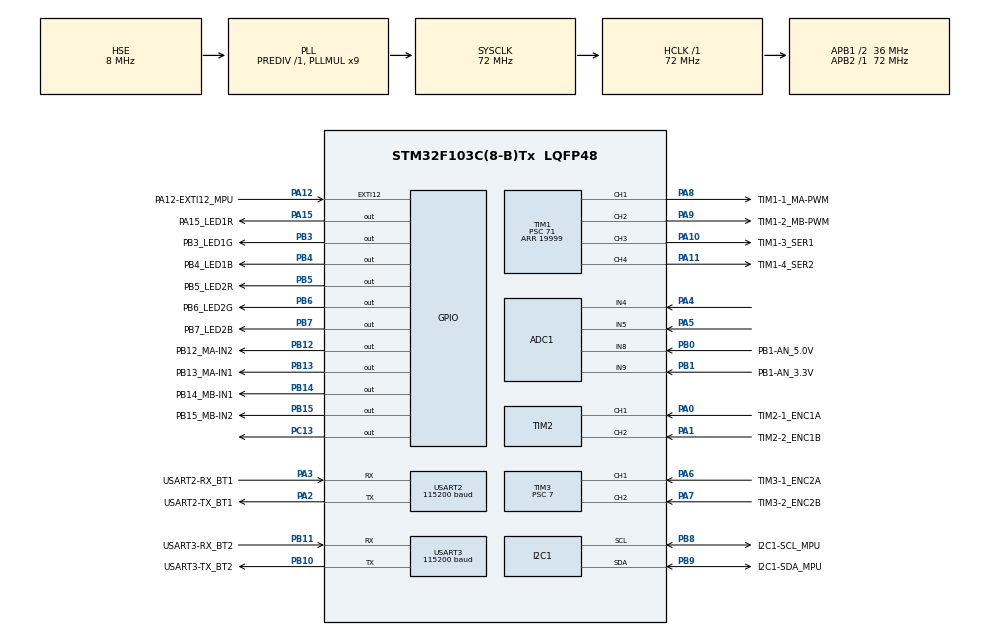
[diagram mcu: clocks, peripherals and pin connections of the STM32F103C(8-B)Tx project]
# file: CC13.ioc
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ADC1.Channel-3\#ChannelRegularConversion=ADC_CHANNEL_5
ADC1.Channel-4\#ChannelRegularConversion=ADC_CHANNEL_4
ADC1.Channel-5\#ChannelRegularConversion=ADC_CHANNEL_4
ADC1.NbrOfConversion=3
ADC1.NbrOfConversionFlag=1
ADC1.Rank-3\#ChannelRegularConversion=1
ADC1.Rank-4\#ChannelRegularConversion=2
ADC1.Rank-5\#ChannelRegularConversion=3
ADC1.SamplingTime-3\#ChannelRegularConversion=ADC_SAMPLETIME_1CYCLE_5
ADC1.SamplingTime-4\#ChannelRegularConversion=ADC_SAMPLETIME_1CYCLE_5
ADC1.SamplingTime-5\#ChannelRegularConversion=ADC_SAMPLETIME_1CYCLE_5
ADC1.master=1
Dma.ADC1.0.Direction=DMA_PERIPH_TO_MEMORY
Dma.ADC1.0.Instance=DMA1_Channel1
Dma.ADC1.0.MemDataAlignment=DMA_MDATAALIGN_WORD
Dma.ADC1.0.MemInc=DMA_MINC_ENABLE
Dma.ADC1.0.Mode=DMA_CIRCULAR
Dma.ADC1.0.PeriphDataAlignment=DMA_PDATAALIGN_WORD
Dma.ADC1.0.PeriphInc=DMA_PINC_DISABLE
Dma.ADC1.0.Priority=DMA_PRIORITY_LOW
Dma.Request0=ADC1
I2C1.I2C_Mode=I2C_Fast
Mcu.Family=STM32F1
Mcu.Name=STM32F103C(8-B)Tx
Mcu.Package=LQFP48
NVIC.DMA1_Channel1_IRQn=true\:0\:0\:false\:false\:true\:false\:true
NVIC.PriorityGroup=NVIC_PRIORITYGROUP_4
NVIC.USART2_IRQn=true\:0\:0\:false\:false\:true\:true\:true
NVIC.USART3_IRQn=true\:0\:0\:false\:false\:true\:true\:true
PA0-WKUP.GPIO_Label=TIM2-1_ENC1A
PA0-WKUP.Signal=S_TIM2_CH1_ETR
PA1.GPIO_Label=TIM2-2_ENC1B
PA1.Signal=S_TIM2_CH2
PA10.GPIO_Label=TIM1-3_SER1
PA10.Signal=S_TIM1_CH3
PA11.GPIO_Label=TIM1-4_SER2
PA11.Signal=S_TIM1_CH4
PA12.GPIO_Label=PA12-EXTI12_MPU
PA12.Signal=GPXTI12
PA13.Mode=Serial_Wire
PA13.Signal=SYS_JTMS-SWDIO
PA14.Mode=Serial_Wire
PA14.Signal=SYS_JTCK-SWCLK
PA15.GPIO_Label=PA15_LED1R
PA15.Signal=GPIO_Output
PA2.GPIO_Label=USART2-TX_BT1
PA2.Mode=Asynchronous
PA2.Signal=USART2_TX
PA3.GPIO_Label=USART2-RX_BT1
PA3.Mode=Asynchronous
PA3.Signal=USART2_RX
PA4.Signal=ADCx_IN4
PA5.Signal=ADCx_IN5
PA6.GPIO_Label=TIM3-1_ENC2A
PA6.Signal=S_TIM3_CH1
PA7.GPIO_Label=TIM3-2_ENC2B
PA7.Signal=S_TIM3_CH2
PA8.GPIO_Label=TIM1-1_MA-PWM
PA8.Signal=S_TIM1_CH1
PA9.GPIO_Label=TIM1-2_MB-PWM
PA9.Signal=S_TIM1_CH2
PB0.GPIO_Label=PB1-AN_5.0V
PB0.Signal=ADCx_IN8
PB1.GPIO_Label=PB1-AN_3.3V
PB1.Signal=ADCx_IN9
PB10.GPIO_Label=USART3-TX_BT2
PB10.Mode=Asynchronous
PB10.Signal=USART3_TX
PB11.GPIO_Label=USART3-RX_BT2
PB11.Mode=Asynchronous
PB11.Signal=USART3_RX
PB12.GPIO_Label=PB12_MA-IN2
PB12.Signal=GPIO_Output
PB13.GPIO_Label=PB13_MA-IN1
PB13.Signal=GPIO_Output
PB14.GPIO_Label=PB14_MB-IN1
PB14.Signal=GPIO_Output
PB15.GPIO_Label=PB15_MB-IN2
PB15.Signal=GPIO_Output
PB3.GPIO_Label=PB3_LED1G
PB3.Signal=GPIO_Output
PB4.GPIO_Label=PB4_LED1B
PB4.Signal=GPIO_Output
PB5.GPIO_Label=PB5_LED2R
PB5.Signal=GPIO_Output
PB6.GPIO_Label=PB6_LED2G
PB6.Signal=GPIO_Output
PB7.GPIO_Label=PB7_LED2B
PB7.Signal=GPIO_Output
PB8.GPIO_Label=I2C1-SCL_MPU
PB8.Mode=I2C
PB8.Signal=I2C1_SCL
PB9.GPIO_Label=I2C1-SDA_MPU
PB9.Mode=I2C
PB9.Signal=I2C1_SDA
PC13-TAMPER-RTC.Signal=GPIO_Output
PD0-OSC_IN.Mode=HSE-External-Oscillator
PD0-OSC_IN.Signal=RCC_OSC_IN
PD1-OSC_OUT.Mode=HSE-External-Oscillator
PD1-OSC_OUT.Signal=RCC_OSC_OUT
ProjectManager.HeapSize=0x200
ProjectManager.StackSize=0x400
ProjectManager.TargetToolchain=STM32CubeIDE
RCC.ADCPresc=RCC_ADCPCLK2_DIV6
RCC.AHBFreq_Value=72000000
RCC.APB1CLKDivider=RCC_HCLK_DIV2
RCC.APB1Freq_Value=36000000
RCC.APB1TimFreq_Value=72000000
RCC.APB2Freq_Value=72000000
RCC.APB2TimFreq_Value=72000000
RCC.EnbaleCSS=true
RCC.HCLKFreq_Value=72000000
RCC.PLLMUL=RCC_PLL_MUL9
RCC.PLLSourceVirtual=RCC_PLLSOURCE_HSE
RCC.SYSCLKFreq_VALUE=72000000
RCC.SYSCLKSource=RCC_SYSCLKSOURCE_PLLCLK
RCC.USBFreq_Value=48000000
RCC.USBPrescaler=RCC_USBCLKSOURCE_PLL_DIV1_5
SH.ADCx_IN4.0=ADC1_IN4,IN4
SH.ADCx_IN5.0=ADC1_IN5,IN5
SH.ADCx_IN8.0=ADC1_IN8,IN8
SH.ADCx_IN9.0=ADC1_IN9,IN9
SH.S_TIM1_CH1.0=TIM1_CH1,PWM Generation1 CH1
SH.S_TIM1_CH2.0=TIM1_CH2,PWM Generation2 CH2
SH.S_TIM1_CH3.0=TIM1_CH3,PWM Generation3 CH3
SH.S_TIM1_CH4.0=TIM1_CH4,PWM Generation4 CH4
SH.S_TIM2_CH1_ETR.0=TIM2_CH1,Encoder_Interface
SH.S_TIM2_CH2.0=TIM2_CH2,Encoder_Interface
SH.S_TIM3_CH1.0=TIM3_CH1,Encoder_Interface
SH.S_TIM3_CH2.0=TIM3_CH2,Encoder_Interface
TIM1.AutoReloadPreload=TIM_AUTORELOAD_PRELOAD_ENABLE
TIM1.Channel-PWM\ Generation1\ CH1=TIM_CHANNEL_1
TIM1.Channel-PWM\ Generation2\ CH2=TIM_CHANNEL_2
TIM1.Channel-PWM\ Generation3\ CH3=TIM_CHANNEL_3
TIM1.Channel-PWM\ Generation4\ CH4=TIM_CHANNEL_4
TIM1.Period=19999
TIM1.Prescaler=71
TIM1.Pulse-PWM\ Generation1\ CH1=0
TIM1.Pulse-PWM\ Generation2\ CH2=0
TIM1.Pulse-PWM\ Generation3\ CH3=0
TIM1.Pulse-PWM\ Generation4\ CH4=0
TIM2.IC1Filter=15
TIM2.IC2Filter=15
TIM3.Period=49999
TIM3.Prescaler=7
TIM4.AutoReloadPreload=TIM_AUTORELOAD_PRELOAD_ENABLE
TIM4.Period=36000
TIM4.Prescaler=0
USART2.BaudRate=115200
USART2.VirtualMode=VM_ASYNC
USART3.BaudRate=115200
USART3.VirtualMode=VM_ASYNC
VP_TIM1_VS_ClockSourceINT.Mode=Internal
VP_TIM4_VS_ClockSourceINT.Mode=Internal
board=custom

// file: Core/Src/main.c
/* USER CODE BEGIN Header */
/**
  ******************************************************************************
  * @file           : main.c
  * @brief          : Main program body
  ******************************************************************************
  * @attention
  *
  * <h2><center>&copy; Copyright (c) 2020 STMicroelectronics.
  * All rights reserved.</center></h2>
  *
  * This software component is licensed by ST under BSD 3-Clause license,
  * the "License"; You may not use this file except in compliance with the
  * License. You may obtain a copy of the License at:
  *                        opensource.org/licenses/BSD-3-Clause
  *
  ******************************************************************************
  */
/* USER CODE END Header */

#include "main.h"
#include "adc.h"
#include "dma.h"
#include "i2c.h"
#include "tim.h"
#include "usart.h"
#include "gpio.h"

void SystemClock_Config(void);
/* USER CODE BEGIN PFP */
extern void extern_setup(void);
extern void extern_loop(void);
extern void extern_UART_Callback(UART_HandleTypeDef *huart);
/* USER CODE END PFP */

int main(void)
{

  /* MCU Configuration--------------------------------------------------------*/

  /* Reset of all peripherals, Initializes the Flash interface and the Systick. */
  HAL_Init();

  /* Configure the system clock */
  SystemClock_Config();

  /* Initialize all configured peripherals */
  MX_GPIO_Init();
  MX_DMA_Init();
  MX_TIM1_Init();
  MX_I2C1_Init();
  MX_TIM3_Init();
  MX_TIM4_Init();
  MX_TIM2_Init();
  MX_USART2_UART_Init();
  MX_USART3_UART_Init();
  MX_ADC1_Init();
  /* USER CODE BEGIN 2 */

  extern_setup();

  /* USER CODE END 2 */

  /* Infinite loop */
  /* USER CODE BEGIN WHILE */
  //HAL_GPIO_WritePin(GPIOC, GPIO_PIN_13, RESET);

  while (1)
  {
    /* USER CODE END WHILE */

    /* USER CODE BEGIN 3 */
	  	extern_loop();
  }
  /* USER CODE END 3 */
}

void SystemClock_Config(void)
{
  RCC_OscInitTypeDef RCC_OscInitStruct = {0};
  RCC_ClkInitTypeDef RCC_ClkInitStruct = {0};
  RCC_PeriphCLKInitTypeDef PeriphClkInit = {0};

  /** Initializes the CPU, AHB and APB busses clocks
  */
  RCC_OscInitStruct.OscillatorType = RCC_OSCILLATORTYPE_HSE;
  RCC_OscInitStruct.HSEState = RCC_HSE_ON;
  RCC_OscInitStruct.HSEPredivValue = RCC_HSE_PREDIV_DIV1;
  RCC_OscInitStruct.HSIState = RCC_HSI_ON;
  RCC_OscInitStruct.PLL.PLLState = RCC_PLL_ON;
  RCC_OscInitStruct.PLL.PLLSource = RCC_PLLSOURCE_HSE;
  RCC_OscInitStruct.PLL.PLLMUL = RCC_PLL_MUL9;
  if (HAL_RCC_OscConfig(&RCC_OscInitStruct) != HAL_OK)
  {
    Error_Handler();
  }
  /** Initializes the CPU, AHB and APB busses clocks
  */
  RCC_ClkInitStruct.ClockType = RCC_CLOCKTYPE_HCLK|RCC_CLOCKTYPE_SYSCLK
                              |RCC_CLOCKTYPE_PCLK1|RCC_CLOCKTYPE_PCLK2;
  RCC_ClkInitStruct.SYSCLKSource = RCC_SYSCLKSOURCE_PLLCLK;
  RCC_ClkInitStruct.AHBCLKDivider = RCC_SYSCLK_DIV1;
  RCC_ClkInitStruct.APB1CLKDivider = RCC_HCLK_DIV2;
  RCC_ClkInitStruct.APB2CLKDivider = RCC_HCLK_DIV1;

  if (HAL_RCC_ClockConfig(&RCC_ClkInitStruct, FLASH_LATENCY_2) != HAL_OK)
  {
    Error_Handler();
  }
  PeriphClkInit.PeriphClockSelection = RCC_PERIPHCLK_ADC;
  PeriphClkInit.AdcClockSelection = RCC_ADCPCLK2_DIV6;
  if (HAL_RCCEx_PeriphCLKConfig(&PeriphClkInit) != HAL_OK)
  {
    Error_Handler();
  }
  /** Enables the Clock Security System
  */
  HAL_RCC_EnableCSS();
}

/* USER CODE BEGIN 4 */

void HAL_UART_RxCpltCallback(UART_HandleTypeDef *huart)
{
	extern_UART_Callback(huart);
}

/* USER CODE END 4 */

void Error_Handler(void)
{
  /* USER CODE BEGIN Error_Handler_Debug */
	/* User can add his own implementation to report the HAL error return state */
	while (1) {
		HAL_GPIO_TogglePin(GPIOC, GPIO_PIN_13);
		HAL_Delay(500);
	}
  /* USER CODE END Error_Handler_Debug */
}

/************************ (C) COPYRIGHT STMicroelectronics *****END OF FILE****/
